VERSION ""

NS_ :

BS_:

BU_: GWM VCU Tester

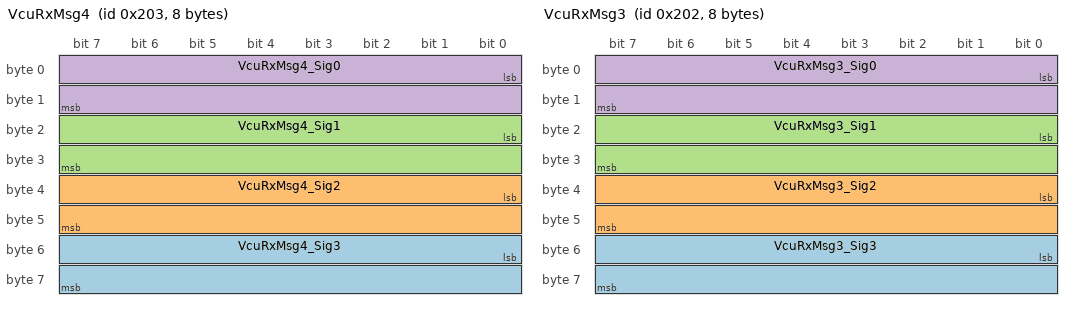
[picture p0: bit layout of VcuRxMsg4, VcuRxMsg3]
BO_ 515 VcuRxMsg4: 8 GWM
 SG_ VcuRxMsg4_Sig3 : 48|16@1- (1,0) [0|0] ""  VCU
 SG_ VcuRxMsg4_Sig2 : 32|16@1- (1,0) [0|0] ""  VCU
 SG_ VcuRxMsg4_Sig1 : 16|16@1- (1,0) [0|0] ""  VCU
 SG_ VcuRxMsg4_Sig0 : 0|16@1- (1,0) [0|0] ""  VCU

BO_ 514 VcuRxMsg3: 8 GWM
 SG_ VcuRxMsg3_Sig3 : 48|16@1- (1,0) [0|0] ""  VCU
 SG_ VcuRxMsg3_Sig2 : 32|16@1- (1,0) [0|0] ""  VCU
 SG_ VcuRxMsg3_Sig1 : 16|16@1- (1,0) [0|0] ""  VCU
 SG_ VcuRxMsg3_Sig0 : 0|16@1- (1,0) [0|0] ""  VCU

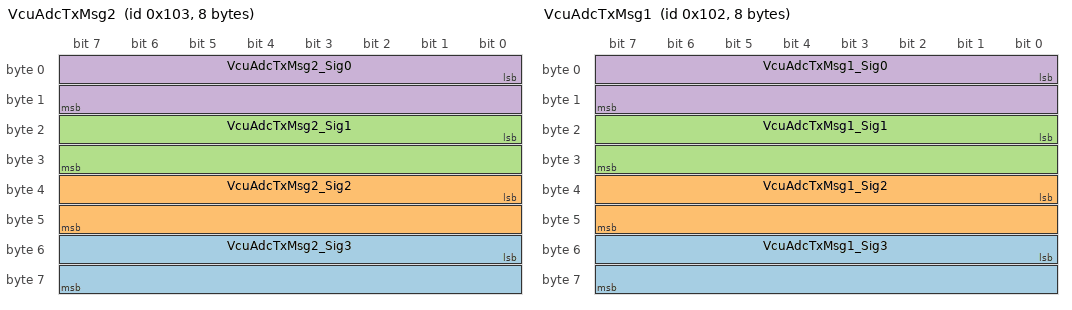
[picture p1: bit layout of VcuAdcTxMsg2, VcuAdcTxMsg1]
BO_ 259 VcuAdcTxMsg2: 8 VCU
 SG_ VcuAdcTxMsg2_Sig3 : 48|16@1- (1,0) [0|0] ""  GWM
 SG_ VcuAdcTxMsg2_Sig2 : 32|16@1- (1,0) [0|0] ""  GWM
 SG_ VcuAdcTxMsg2_Sig1 : 16|16@1- (1,0) [0|0] ""  GWM
 SG_ VcuAdcTxMsg2_Sig0 : 0|16@1- (1,0) [0|0] ""  GWM

BO_ 258 VcuAdcTxMsg1: 8 VCU
 SG_ VcuAdcTxMsg1_Sig3 : 48|16@1- (1,0) [0|0] ""  GWM
 SG_ VcuAdcTxMsg1_Sig2 : 32|16@1- (1,0) [0|0] ""  GWM
 SG_ VcuAdcTxMsg1_Sig1 : 16|16@1- (1,0) [0|0] ""  GWM
 SG_ VcuAdcTxMsg1_Sig0 : 0|16@1- (1,0) [0|0] ""  GWM

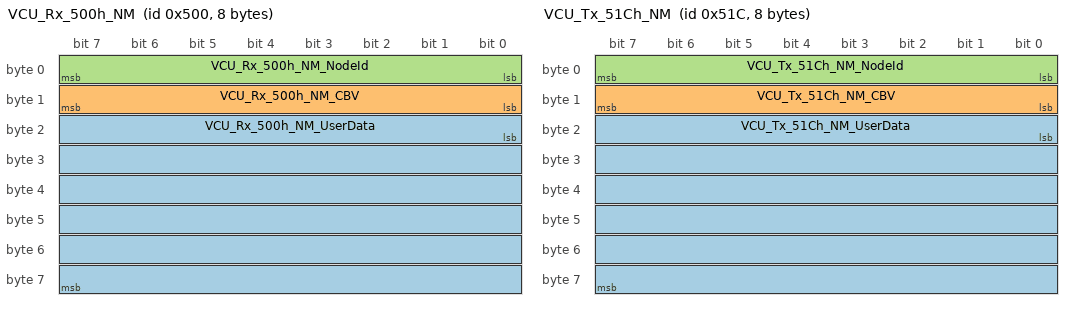
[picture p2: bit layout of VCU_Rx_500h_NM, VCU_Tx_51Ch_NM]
BO_ 1280 VCU_Rx_500h_NM: 8 GWM
 SG_ VCU_Rx_500h_NM_UserData : 16|48@1+ (1,0) [0|0] ""  VCU
 SG_ VCU_Rx_500h_NM_CBV : 8|8@1+ (1,0) [0|0] ""  VCU
 SG_ VCU_Rx_500h_NM_NodeId : 0|8@1+ (1,0) [0|0] ""  VCU

BO_ 1308 VCU_Tx_51Ch_NM: 8 VCU
 SG_ VCU_Tx_51Ch_NM_UserData : 16|48@1+ (1,0) [0|0] ""  GWM
 SG_ VCU_Tx_51Ch_NM_CBV : 8|8@1+ (1,0) [0|0] ""  GWM
 SG_ VCU_Tx_51Ch_NM_NodeId : 0|8@1+ (1,0) [0|0] ""  GWM

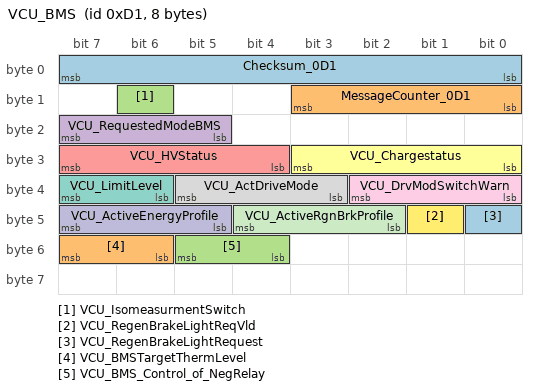
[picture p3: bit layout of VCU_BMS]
BO_ 209 VCU_BMS: 8 VCU
 SG_ Checksum_0D1 : 7|8@0+ (1,0) [0|255] ""  GWM
 SG_ MessageCounter_0D1 : 11|4@0+ (1,0) [0|15] ""  GWM
 SG_ VCU_IsomeasurmentSwitch : 14|1@0+ (1,0) [0|1] ""  GWM
 SG_ VCU_RequestedModeBMS : 23|3@0+ (1,0) [0|7] ""  GWM
 SG_ VCU_HVStatus : 31|4@0+ (1,0) [0|5] ""  GWM
 SG_ VCU_Chargestatus : 27|4@0+ (1,0) [0|14] ""  GWM
 SG_ VCU_LimitLevel : 39|2@0+ (1,0) [0|3] ""  GWM
 SG_ VCU_ActDriveMode : 37|3@0+ (1,0) [0|4] ""  GWM
 SG_ VCU_DrvModSwitchWarn : 34|3@0+ (1,0) [0|7] ""  GWM
 SG_ VCU_ActiveEnergyProfile : 47|3@0+ (1,0) [0|7] ""  GWM
 SG_ VCU_ActiveRgnBrkProfile : 44|3@0+ (1,0) [0|7] ""  GWM
 SG_ VCU_RegenBrakeLightReqVld : 41|1@0+ (1,0) [0|1] ""  GWM
 SG_ VCU_RegenBrakeLightRequest : 40|1@0+ (1,0) [0|1] ""  GWM
 SG_ VCU_BMSTargetThermLevel : 55|2@0+ (1,0) [0|3] ""  GWM
 SG_ VCU_BMS_Control_of_NegRelay : 53|2@0+ (1,0) [0|2] ""  GWM

BO_ 188 IBS_Status_06: 8 GWM
 SG_ Checksum_0BC : 7|8@0+ (1,0) [0|255] ""  VCU
 SG_ MessageCounter_0BC : 11|4@0+ (1,0) [0|15] ""  VCU
 SG_ IBS_HBAActive : 46|1@0+ (1,0) [0|1] ""  VCU
 SG_ IBS_ESCOffSts : 45|1@0+ (1,0) [0|1] ""  VCU
 SG_ IBS_RWUActive : 44|1@0+ (1,0) [0|1] ""  VCU
 SG_ IBS_RWUAvailable : 43|1@0+ (1,0) [0|1] ""  VCU
 SG_ IBS_MaintenaceMode : 42|1@0+ (1,0) [0|1] ""  VCU
 SG_ IBS_RollerbenchMode : 41|1@0+ (1,0) [0|1] ""  VCU
 SG_ IBS_FactoryMode : 40|1@0+ (1,0) [0|1] ""  VCU
 SG_ IBS_AVHSts : 55|2@0+ (1,0) [0|2] ""  VCU
 SG_ IBS_ESClampdisplay : 53|2@0+ (1,0) [0|2] ""  VCU
 SG_ IBS_HDCSts : 51|2@0+ (1,0) [0|2] ""  VCU
 SG_ IBS_BrakeFluidWarning : 49|2@0+ (1,0) [0|3] ""  VCU
 SG_ IBS_EPBFailureStatus : 63|2@0+ (1,0) [0|3] ""  VCU
 SG_ IBS_TireMonSysSts : 61|1@0+ (1,0) [0|1] ""  VCU
 SG_ IBS_TPMS_ResetSts : 60|1@0+ (1,0) [0|1] ""  VCU
 SG_ IBS_TireWarnReLe : 59|1@0+ (1,0) [0|1] ""  VCU
 SG_ IBS_TireWarnReRi : 58|1@0+ (1,0) [0|1] ""  VCU
 SG_ IBS_TireWarnFrntLe : 57|1@0+ (1,0) [0|1] ""  VCU
 SG_ IBS_TireWarnFrntRi : 56|1@0+ (1,0) [0|1] ""  VCU

BA_DEF_ BO_  "VFrameFormat" ENUM  "StandardCAN","ExtendedCAN","reserved","reserved","reserved","reserved","reserved","reserved","reserved","reserved","reserved","reserved","reserved","reserved","StandardCAN_FD","ExtendedCAN_FD";
BA_DEF_ BO_  "GenMsgCycleTime" INT 0 0;
BA_DEF_ BO_  "GenMsgSendType" ENUM  "Cyclic","NotUsed","NotUsed","NotUsed","NotUsed","NotUsed","NotUsed","IfActive","NoMsgSendType","NotUsed";
BA_DEF_ SG_  "GenSigSendType" ENUM  "Cyclic","OnWrite","OnWriteWithRepetition","OnChange","OnChangeWithRepetition","IfActive","IfActiveWithRepetition","NoSigSendType","NotUsed","NotUsed","NotUsed","NotUsed","NotUsed";
BA_DEF_  "Baudrate" INT 0 1000000;
BA_DEF_  "BusType" STRING ;
BA_DEF_  "NmType" STRING ;
BA_DEF_  "Manufacturer" STRING ;
BA_DEF_ BU_  "NodeLayerModules" STRING ;
BA_DEF_ BO_  "NmMessage" ENUM  "no","yes";
BA_DEF_  "NmAsrWaitBusSleepTime" INT 0 65535;
BA_DEF_  "NmAsrTimeoutTime" INT 1 65535;
BA_DEF_  "NmAsrRepeatMessageTime" INT 0 65535;
BA_DEF_ BU_  "NmAsrNodeIdentifier" HEX 0 255;
BA_DEF_ BU_  "NmAsrNode" ENUM  "no","yes";
BA_DEF_  "NmAsrMessageCount" INT 1 256;
BA_DEF_ BO_  "NmAsrMessage" ENUM  "no","yes";
BA_DEF_ BU_  "NmAsrCanMsgReducedTime" INT 1 65535;
BA_DEF_  "NmAsrCanMsgCycleTime" INT 1 65535;
BA_DEF_  "NmAsrBaseAddress" HEX 0 2047;
BA_DEF_ BU_  "ILUsed" ENUM  "no","yes";
BA_DEF_ BO_  "GenMsgILSupport" ENUM  "no","yes";
BA_DEF_  "DBName" STRING ;
BA_DEF_DEF_  "VFrameFormat" "ExtendedCAN_FD";
BA_DEF_DEF_  "GenMsgCycleTime" 0;
BA_DEF_DEF_  "GenMsgSendType" "Cyclic";
BA_DEF_DEF_  "GenSigSendType" "Cyclic";
BA_DEF_DEF_  "Baudrate" 500000;
BA_DEF_DEF_  "BusType" "";
BA_DEF_DEF_  "NmType" "";
BA_DEF_DEF_  "Manufacturer" "Vector";
BA_DEF_DEF_  "NodeLayerModules" " ";
BA_DEF_DEF_  "NmMessage" "no";
BA_DEF_DEF_  "NmAsrWaitBusSleepTime" 2000;
BA_DEF_DEF_  "NmAsrTimeoutTime" 2000;
BA_DEF_DEF_  "NmAsrRepeatMessageTime" 1500;
BA_DEF_DEF_  "NmAsrNodeIdentifier" 28;
BA_DEF_DEF_  "NmAsrNode" "yes";
BA_DEF_DEF_  "NmAsrMessageCount" 128;
BA_DEF_DEF_  "NmAsrMessage" "no";
BA_DEF_DEF_  "NmAsrCanMsgReducedTime" 320;
BA_DEF_DEF_  "NmAsrCanMsgCycleTime" 500;
BA_DEF_DEF_  "NmAsrBaseAddress" 1024;
BA_DEF_DEF_  "ILUsed" "yes";
BA_DEF_DEF_  "GenMsgILSupport" "yes";
BA_DEF_DEF_  "DBName" "";
BA_ "NmType" "NmAsr";
BA_ "BusType" "CAN";
BA_ "DBName" "TC37X_VCU_CAN01";
BA_ "GenMsgCycleTime" BO_ 515 500;
BA_ "VFrameFormat" BO_ 515 0;
BA_ "GenMsgCycleTime" BO_ 514 500;
BA_ "VFrameFormat" BO_ 514 0;
BA_ "GenMsgCycleTime" BO_ 259 500;
BA_ "VFrameFormat" BO_ 259 0;
BA_ "GenMsgCycleTime" BO_ 258 500;
BA_ "VFrameFormat" BO_ 258 0;
BA_ "NmMessage" BO_ 1280 1;
BA_ "NmAsrMessage" BO_ 1280 1;
BA_ "GenMsgCycleTime" BO_ 1280 500;
BA_ "VFrameFormat" BO_ 1280 0;
BA_ "NmMessage" BO_ 1308 1;
BA_ "NmAsrMessage" BO_ 1308 1;
BA_ "GenMsgCycleTime" BO_ 1308 500;
BA_ "VFrameFormat" BO_ 1308 0;
BA_ "VFrameFormat" BO_ 209 0;
BA_ "GenMsgCycleTime" BO_ 209 20;
BA_ "VFrameFormat" BO_ 188 0;
BA_ "GenMsgCycleTime" BO_ 188 20;
SIG_GROUP_ 209 VCU_BMS_Signal_Group 1 : Checksum_0D1 MessageCounter_0D1 VCU_IsomeasurmentSwitch VCU_RequestedModeBMS VCU_HVStatus VCU_Chargestatus VCU_LimitLevel VCU_ActDriveMode VCU_DrvModSwitchWarn VCU_ActiveEnergyProfile VCU_ActiveRgnBrkProfile VCU_RegenBrakeLightReqVld VCU_RegenBrakeLightRequest VCU_BMSTargetThermLevel VCU_BMS_Control_of_NegRelay;
SIG_GROUP_ 188 IBS_Status_06_Signal_Group 1 : Checksum_0BC MessageCounter_0BC IBS_HBAActive IBS_ESCOffSts IBS_RWUActive IBS_RWUAvailable IBS_MaintenaceMode IBS_RollerbenchMode IBS_FactoryMode IBS_AVHSts IBS_ESClampdisplay IBS_HDCSts IBS_BrakeFluidWarning IBS_EPBFailureStatus IBS_TireMonSysSts IBS_TPMS_ResetSts IBS_TireWarnReLe IBS_TireWarnReRi IBS_TireWarnFrntLe IBS_TireWarnFrntRi;
